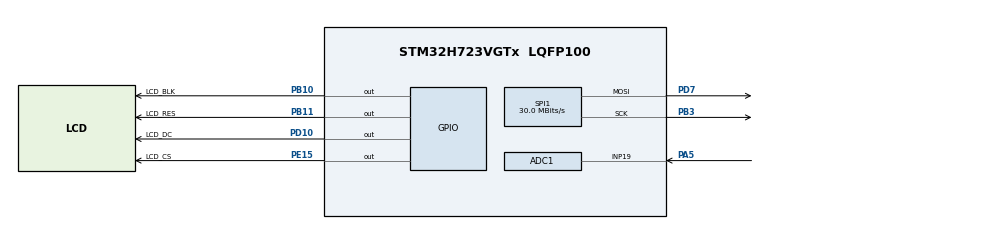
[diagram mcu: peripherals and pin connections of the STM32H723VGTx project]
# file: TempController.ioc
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ADC1.Channel-0\#ChannelRegularConversion=ADC_CHANNEL_19
ADC1.ClockPrescaler=ADC_CLOCK_ASYNC_DIV64
ADC1.ContinuousConvMode=ENABLE
ADC1.ConversionDataManagement=ADC_CONVERSIONDATA_DMA_CIRCULAR
ADC1.NbrOfConversionFlag=1
ADC1.OffsetNumber-0\#ChannelRegularConversion=ADC_OFFSET_NONE
ADC1.OffsetSignedSaturation-0\#ChannelRegularConversion=DISABLE
ADC1.Rank-0\#ChannelRegularConversion=1
ADC1.SamplingTime-0\#ChannelRegularConversion=ADC_SAMPLETIME_32CYCLES_5
ADC1.master=1
DMA2D.ColorMode=DMA2D_OUTPUT_RGB565
Dma.ADC1.0.Direction=DMA_PERIPH_TO_MEMORY
Dma.ADC1.0.EventEnable=DISABLE
Dma.ADC1.0.FIFOMode=DMA_FIFOMODE_DISABLE
Dma.ADC1.0.Instance=DMA2_Stream0
Dma.ADC1.0.MemDataAlignment=DMA_MDATAALIGN_HALFWORD
Dma.ADC1.0.MemInc=DMA_MINC_ENABLE
Dma.ADC1.0.Mode=DMA_CIRCULAR
Dma.ADC1.0.PeriphDataAlignment=DMA_PDATAALIGN_HALFWORD
Dma.ADC1.0.PeriphInc=DMA_PINC_DISABLE
Dma.ADC1.0.Polarity=HAL_DMAMUX_REQ_GEN_RISING
Dma.ADC1.0.Priority=DMA_PRIORITY_LOW
Dma.ADC1.0.RequestNumber=1
Dma.ADC1.0.SignalID=NONE
Dma.ADC1.0.SyncEnable=DISABLE
Dma.ADC1.0.SyncPolarity=HAL_DMAMUX_SYNC_NO_EVENT
Dma.ADC1.0.SyncRequestNumber=1
Dma.ADC1.0.SyncSignalID=NONE
Dma.Request0=ADC1
Dma.Request1=SPI1_TX
Dma.SPI1_TX.1.Direction=DMA_MEMORY_TO_PERIPH
Dma.SPI1_TX.1.EventEnable=DISABLE
Dma.SPI1_TX.1.FIFOMode=DMA_FIFOMODE_DISABLE
Dma.SPI1_TX.1.Instance=DMA1_Stream0
Dma.SPI1_TX.1.MemDataAlignment=DMA_MDATAALIGN_HALFWORD
Dma.SPI1_TX.1.MemInc=DMA_MINC_ENABLE
Dma.SPI1_TX.1.Mode=DMA_NORMAL
Dma.SPI1_TX.1.PeriphDataAlignment=DMA_PDATAALIGN_HALFWORD
Dma.SPI1_TX.1.PeriphInc=DMA_PINC_DISABLE
Dma.SPI1_TX.1.Polarity=HAL_DMAMUX_REQ_GEN_RISING
Dma.SPI1_TX.1.Priority=DMA_PRIORITY_VERY_HIGH
Dma.SPI1_TX.1.RequestNumber=1
Dma.SPI1_TX.1.SignalID=NONE
Dma.SPI1_TX.1.SyncEnable=DISABLE
Dma.SPI1_TX.1.SyncPolarity=HAL_DMAMUX_SYNC_NO_EVENT
Dma.SPI1_TX.1.SyncRequestNumber=1
Dma.SPI1_TX.1.SyncSignalID=NONE
FREERTOS.Queues01=stickQueue,16,uint16_t,0,Dynamic,NULL,NULL
FREERTOS.Tasks01=lcdTask,24,8192,LcdTask,As weak,NULL,Static,lcdTaskBuffer,lcdTaskControlBlock;stickTask,40,2048,StickTask,As weak,NULL,Static,stickTaskBuffer,stickTaskControlBlock
FREERTOS.configENABLE_FPU=1
Mcu.Family=STM32H7
Mcu.Name=STM32H723VGTx
Mcu.Package=LQFP100
NVIC.DMA1_Stream0_IRQn=true\:5\:0\:false\:false\:true\:true\:false\:true\:true
NVIC.DMA2_Stream0_IRQn=true\:5\:0\:false\:false\:true\:false\:false\:true\:true
NVIC.PriorityGroup=NVIC_PRIORITYGROUP_4
NVIC.SPI1_IRQn=true\:5\:0\:false\:false\:true\:true\:false\:true\:true
NVIC.TIM8_UP_TIM13_IRQn=true\:15\:0\:false\:false\:true\:false\:false\:true\:true
NVIC.TimeBase=TIM8_UP_TIM13_IRQn
NVIC.TimeBaseIP=TIM8
PA13(JTMS/SWDIO).Mode=Serial_Wire
PA13(JTMS/SWDIO).Signal=DEBUG_JTMS-SWDIO
PA14(JTCK/SWCLK).Mode=Serial_Wire
PA14(JTCK/SWCLK).Signal=DEBUG_JTCK-SWCLK
PA5.Signal=ADCx_INP19
PB10.GPIO_Label=LCD_BLK
PB10.GPIO_PuPd=GPIO_NOPULL
PB10.GPIO_Speed=GPIO_SPEED_FREQ_VERY_HIGH
PB10.Signal=GPIO_Output
PB11.GPIO_Label=LCD_RES
PB11.GPIO_PuPd=GPIO_NOPULL
PB11.GPIO_Speed=GPIO_SPEED_FREQ_VERY_HIGH
PB11.Signal=GPIO_Output
PB3(JTDO/TRACESWO).GPIO_Speed=GPIO_SPEED_FREQ_VERY_HIGH
PB3(JTDO/TRACESWO).Mode=TX_Only_Simplex_Unidirect_Master
PB3(JTDO/TRACESWO).Signal=SPI1_SCK
PD10.GPIO_Label=LCD_DC
PD10.GPIO_PuPd=GPIO_PULLUP
PD10.GPIO_Speed=GPIO_SPEED_FREQ_VERY_HIGH
PD10.Signal=GPIO_Output
PD7.GPIO_Speed=GPIO_SPEED_FREQ_VERY_HIGH
PD7.Mode=TX_Only_Simplex_Unidirect_Master
PD7.Signal=SPI1_MOSI
PE15.GPIO_Label=LCD_CS
PE15.GPIO_PuPd=GPIO_PULLUP
PE15.GPIO_Speed=GPIO_SPEED_FREQ_VERY_HIGH
PE15.Signal=GPIO_Output
PH0-OSC_IN.Mode=HSE-External-Oscillator
PH0-OSC_IN.Signal=RCC_OSC_IN
PH1-OSC_OUT.Mode=HSE-External-Oscillator
PH1-OSC_OUT.Signal=RCC_OSC_OUT
ProjectManager.HeapSize=0x200
ProjectManager.StackSize=0x400
ProjectManager.TargetToolchain=CMake
RCC.ADCFreq_Value=60000000
RCC.APB1Freq_Value=137500000
RCC.APB2Freq_Value=137500000
RCC.APB3Freq_Value=137500000
RCC.APB4Freq_Value=137500000
RCC.CortexFreq_Value=550000000
RCC.D1PPRE=RCC_APB3_DIV2
RCC.D2PPRE1=RCC_APB1_DIV2
RCC.D2PPRE2=RCC_APB2_DIV2
RCC.D3PPRE=RCC_APB4_DIV2
RCC.DIVM1=3
RCC.DIVM2=2
RCC.DIVN1=68
RCC.DIVN2=20
RCC.DIVN3=128
RCC.DIVP1=1
RCC.DIVP2=4
RCC.HCLKFreq_Value=275000000
RCC.HPRE=RCC_HCLK_DIV2
RCC.HSE_VALUE=24000000
RCC.PLL2FRACN=0
RCC.PLL3FRACN=0
RCC.PLLFRACN=6144
RCC.PLLSourceVirtual=RCC_PLLSOURCE_HSE
RCC.SPI123CLockSelection=RCC_SPI123CLKSOURCE_PLL2
RCC.SYSCLKFreq_VALUE=550000000
RCC.SYSCLKSource=RCC_SYSCLKSOURCE_PLLCLK
RCC.USBFreq_Value=275000000
SH.ADCx_INP19.0=ADC1_INP19,IN19-Single-Ended
SPI1.BaudRatePrescaler=SPI_BAUDRATEPRESCALER_2
SPI1.CLKPolarity=SPI_POLARITY_HIGH
SPI1.CalculateBaudRate=30.0 MBits/s
SPI1.DataSize=SPI_DATASIZE_16BIT
SPI1.Direction=SPI_DIRECTION_2LINES_TXONLY
SPI1.FifoThreshold=SPI_FIFO_THRESHOLD_01DATA
SPI1.Mode=SPI_MODE_MASTER
SPI1.NSSPMode=SPI_NSS_PULSE_ENABLE
SPI1.VirtualType=VM_MASTER
VP_DMA2D_VS_DMA2D.Mode=DMA2D_Activate
VP_FREERTOS_VS_CMSIS_V2.Mode=CMSIS_V2
VP_MEMORYMAP_VS_MEMORYMAP.Mode=CurAppReg
VP_SYS_VS_tim8.Mode=TIM8
board=custom

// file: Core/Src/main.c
/* USER CODE BEGIN Header */
/**
  ******************************************************************************
  * @file           : main.c
  * @brief          : Main program body
  ******************************************************************************
  * @attention
  *
  * Copyright (c) 2026 STMicroelectronics.
  * All rights reserved.
  *
  * This software is licensed under terms that can be found in the LICENSE file
  * in the root directory of this software component.
  * If no LICENSE file comes with this software, it is provided AS-IS.
  *
  ******************************************************************************
  */
/* USER CODE END Header */
#include "main.h"
#include "cmsis_os.h"
#include "adc.h"
#include "dma.h"
#include "dma2d.h"
#include "spi.h"
#include "gpio.h"

/* USER CODE BEGIN PD */
#define BUS_SPI1_POLL_TIMEOUT 0x1000U
/* USER CODE END PD */

/* USER CODE BEGIN PV */
volatile float g_temp_current_c = 24.3f;
volatile float g_temp_setpoint_c = 50.0f;

/* USER CODE END PV */

void SystemClock_Config(void);
void PeriphCommonClock_Config(void);
void MX_FREERTOS_Init(void);

int main(void)
{

  /* MCU Configuration--------------------------------------------------------*/

  /* Reset of all peripherals, Initializes the Flash interface and the Systick. */
  HAL_Init();

  /* Configure the system clock */
  SystemClock_Config();

  /* Configure the peripherals common clocks */
  PeriphCommonClock_Config();

  /* Initialize all configured peripherals */
  MX_GPIO_Init();
  MX_DMA_Init();
  MX_ADC1_Init();
  MX_SPI1_Init();
  MX_DMA2D_Init();

  /* Init scheduler */
  osKernelInitialize();  /* Call init function for freertos objects (in cmsis_os2.c) */
  MX_FREERTOS_Init();

  /* Start scheduler */
  osKernelStart();

  /* We should never get here as control is now taken by the scheduler */

  /* Infinite loop */
    while (1)
    {

    }
}

void SystemClock_Config(void)
{
  RCC_OscInitTypeDef RCC_OscInitStruct = {0};
  RCC_ClkInitTypeDef RCC_ClkInitStruct = {0};

  /** Supply configuration update enable
  */
  HAL_PWREx_ConfigSupply(PWR_LDO_SUPPLY);

  /** Configure the main internal regulator output voltage
  */
  __HAL_PWR_VOLTAGESCALING_CONFIG(PWR_REGULATOR_VOLTAGE_SCALE0);

  while(!__HAL_PWR_GET_FLAG(PWR_FLAG_VOSRDY)) {}

  /** Initializes the RCC Oscillators according to the specified parameters
  * in the RCC_OscInitTypeDef structure.
  */
  RCC_OscInitStruct.OscillatorType = RCC_OSCILLATORTYPE_HSE;
  RCC_OscInitStruct.HSEState = RCC_HSE_ON;
  RCC_OscInitStruct.PLL.PLLState = RCC_PLL_ON;
  RCC_OscInitStruct.PLL.PLLSource = RCC_PLLSOURCE_HSE;
  RCC_OscInitStruct.PLL.PLLM = 3;
  RCC_OscInitStruct.PLL.PLLN = 68;
  RCC_OscInitStruct.PLL.PLLP = 1;
  RCC_OscInitStruct.PLL.PLLQ = 2;
  RCC_OscInitStruct.PLL.PLLR = 2;
  RCC_OscInitStruct.PLL.PLLRGE = RCC_PLL1VCIRANGE_3;
  RCC_OscInitStruct.PLL.PLLVCOSEL = RCC_PLL1VCOWIDE;
  RCC_OscInitStruct.PLL.PLLFRACN = 6144;
  if (HAL_RCC_OscConfig(&RCC_OscInitStruct) != HAL_OK)
  {
    Error_Handler();
  }

  /** Initializes the CPU, AHB and APB buses clocks
  */
  RCC_ClkInitStruct.ClockType = RCC_CLOCKTYPE_HCLK|RCC_CLOCKTYPE_SYSCLK
                              |RCC_CLOCKTYPE_PCLK1|RCC_CLOCKTYPE_PCLK2
                              |RCC_CLOCKTYPE_D3PCLK1|RCC_CLOCKTYPE_D1PCLK1;
  RCC_ClkInitStruct.SYSCLKSource = RCC_SYSCLKSOURCE_PLLCLK;
  RCC_ClkInitStruct.SYSCLKDivider = RCC_SYSCLK_DIV1;
  RCC_ClkInitStruct.AHBCLKDivider = RCC_HCLK_DIV2;
  RCC_ClkInitStruct.APB3CLKDivider = RCC_APB3_DIV2;
  RCC_ClkInitStruct.APB1CLKDivider = RCC_APB1_DIV2;
  RCC_ClkInitStruct.APB2CLKDivider = RCC_APB2_DIV2;
  RCC_ClkInitStruct.APB4CLKDivider = RCC_APB4_DIV2;

  if (HAL_RCC_ClockConfig(&RCC_ClkInitStruct, FLASH_LATENCY_3) != HAL_OK)
  {
    Error_Handler();
  }
}

void PeriphCommonClock_Config(void)
{
  RCC_PeriphCLKInitTypeDef PeriphClkInitStruct = {0};

  /** Initializes the peripherals clock
  */
  PeriphClkInitStruct.PeriphClockSelection = RCC_PERIPHCLK_ADC|RCC_PERIPHCLK_SPI1;
  PeriphClkInitStruct.PLL2.PLL2M = 2;
  PeriphClkInitStruct.PLL2.PLL2N = 20;
  PeriphClkInitStruct.PLL2.PLL2P = 4;
  PeriphClkInitStruct.PLL2.PLL2Q = 2;
  PeriphClkInitStruct.PLL2.PLL2R = 2;
  PeriphClkInitStruct.PLL2.PLL2RGE = RCC_PLL2VCIRANGE_3;
  PeriphClkInitStruct.PLL2.PLL2VCOSEL = RCC_PLL2VCOWIDE;
  PeriphClkInitStruct.PLL2.PLL2FRACN = 0;
  PeriphClkInitStruct.Spi123ClockSelection = RCC_SPI123CLKSOURCE_PLL2;
  PeriphClkInitStruct.AdcClockSelection = RCC_ADCCLKSOURCE_PLL2;
  if (HAL_RCCEx_PeriphCLKConfig(&PeriphClkInitStruct) != HAL_OK)
  {
    Error_Handler();
  }
}

void HAL_TIM_PeriodElapsedCallback(TIM_HandleTypeDef *htim)
{
  if (htim->Instance == TIM8)
  {
    HAL_IncTick();
  }
}

void Error_Handler(void)
{
    __disable_irq();
    while (1)
    {
    }
}

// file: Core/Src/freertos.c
/* USER CODE BEGIN Header */
/**
  ******************************************************************************
  * File Name          : freertos.c
  * Description        : Code for freertos applications
  ******************************************************************************
  * @attention
  *
  * Copyright (c) 2026 STMicroelectronics.
  * All rights reserved.
  *
  * This software is licensed under terms that can be found in the LICENSE file
  * in the root directory of this software component.
  * If no LICENSE file comes with this software, it is provided AS-IS.
  *
  ******************************************************************************
  */
/* USER CODE END Header */

#include "FreeRTOS.h"
#include "task.h"
#include "main.h"
#include "cmsis_os.h"

typedef StaticTask_t osStaticThreadDef_t;

/* Definitions for lcdTask */
osThreadId_t lcdTaskHandle;
uint32_t lcdTaskBuffer[ 8192 ];
osStaticThreadDef_t lcdTaskControlBlock;
const osThreadAttr_t lcdTask_attributes = {
  .name = "lcdTask",
  .cb_mem = &lcdTaskControlBlock,
  .cb_size = sizeof(lcdTaskControlBlock),
  .stack_mem = &lcdTaskBuffer[0],
  .stack_size = sizeof(lcdTaskBuffer),
  .priority = (osPriority_t) osPriorityNormal,
};
/* Definitions for stickTask */
osThreadId_t stickTaskHandle;
uint32_t stickTaskBuffer[ 2048 ];
osStaticThreadDef_t stickTaskControlBlock;
const osThreadAttr_t stickTask_attributes = {
  .name = "stickTask",
  .cb_mem = &stickTaskControlBlock,
  .cb_size = sizeof(stickTaskControlBlock),
  .stack_mem = &stickTaskBuffer[0],
  .stack_size = sizeof(stickTaskBuffer),
  .priority = (osPriority_t) osPriorityHigh,
};
/* Definitions for stickQueue */
osMessageQueueId_t stickQueueHandle;
const osMessageQueueAttr_t stickQueue_attributes = {
  .name = "stickQueue"
};

void LcdTask(void *argument);
void StickTask(void *argument);

void MX_FREERTOS_Init(void); /* (MISRA C 2004 rule 8.1) */

void MX_FREERTOS_Init(void) {

  /* Create the queue(s) */
  /* creation of stickQueue */
  stickQueueHandle = osMessageQueueNew (16, sizeof(uint16_t), &stickQueue_attributes);

  /* Create the thread(s) */
  /* creation of lcdTask */
  lcdTaskHandle = osThreadNew(LcdTask, NULL, &lcdTask_attributes);

  /* creation of stickTask */
  stickTaskHandle = osThreadNew(StickTask, NULL, &stickTask_attributes);

}

__weak void LcdTask(void *argument)
{
  for(;;)
  {
    osDelay(1);
  }
}

__weak void StickTask(void *argument)
{
  for(;;)
  {
    osDelay(1);
  }
}
